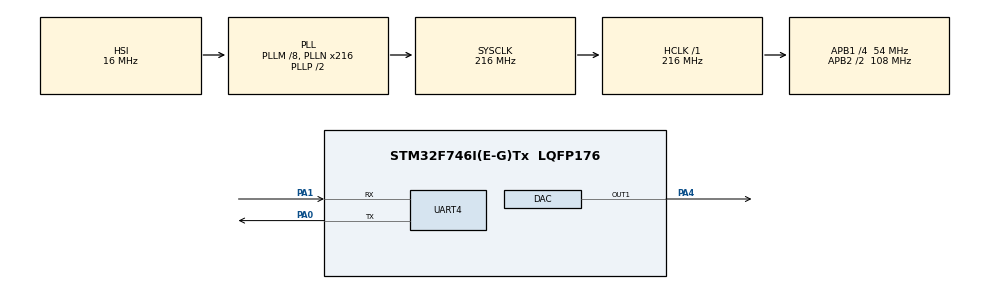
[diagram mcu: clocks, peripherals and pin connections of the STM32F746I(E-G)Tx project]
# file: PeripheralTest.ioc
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DAC.DAC_Trigger=DAC_TRIGGER_T2_TRGO
Dma.DAC1.2.Direction=DMA_MEMORY_TO_PERIPH
Dma.DAC1.2.FIFOMode=DMA_FIFOMODE_DISABLE
Dma.DAC1.2.Instance=DMA1_Stream5
Dma.DAC1.2.MemDataAlignment=DMA_MDATAALIGN_HALFWORD
Dma.DAC1.2.MemInc=DMA_MINC_ENABLE
Dma.DAC1.2.Mode=DMA_CIRCULAR
Dma.DAC1.2.PeriphDataAlignment=DMA_PDATAALIGN_HALFWORD
Dma.DAC1.2.PeriphInc=DMA_PINC_DISABLE
Dma.DAC1.2.Priority=DMA_PRIORITY_LOW
Dma.Request0=UART4_RX
Dma.Request1=UART4_TX
Dma.Request2=DAC1
Dma.UART4_RX.0.Direction=DMA_PERIPH_TO_MEMORY
Dma.UART4_RX.0.FIFOMode=DMA_FIFOMODE_DISABLE
Dma.UART4_RX.0.Instance=DMA1_Stream2
Dma.UART4_RX.0.MemDataAlignment=DMA_MDATAALIGN_BYTE
Dma.UART4_RX.0.MemInc=DMA_MINC_ENABLE
Dma.UART4_RX.0.Mode=DMA_NORMAL
Dma.UART4_RX.0.PeriphDataAlignment=DMA_PDATAALIGN_BYTE
Dma.UART4_RX.0.PeriphInc=DMA_PINC_DISABLE
Dma.UART4_RX.0.Priority=DMA_PRIORITY_LOW
Dma.UART4_TX.1.Direction=DMA_MEMORY_TO_PERIPH
Dma.UART4_TX.1.FIFOMode=DMA_FIFOMODE_DISABLE
Dma.UART4_TX.1.Instance=DMA1_Stream4
Dma.UART4_TX.1.MemDataAlignment=DMA_MDATAALIGN_BYTE
Dma.UART4_TX.1.MemInc=DMA_MINC_ENABLE
Dma.UART4_TX.1.Mode=DMA_NORMAL
Dma.UART4_TX.1.PeriphDataAlignment=DMA_PDATAALIGN_BYTE
Dma.UART4_TX.1.PeriphInc=DMA_PINC_DISABLE
Dma.UART4_TX.1.Priority=DMA_PRIORITY_LOW
FREERTOS.BinarySemaphores01=usart4Sem
FREERTOS.Tasks01=defaultTask,0,128,StartDefaultTask,Default;USARTHandle,0,128,StartUSARTTask,Default
FREERTOS.configUSE_COUNTING_SEMAPHORES=1
Mcu.Family=STM32F7
Mcu.Name=STM32F746I(E-G)Tx
Mcu.Package=LQFP176
NVIC.DMA1_Stream2_IRQn=true\:5\:0\:false\:false\:true\:true
NVIC.DMA1_Stream4_IRQn=true\:5\:0\:false\:false\:true\:true
NVIC.DMA1_Stream5_IRQn=true\:5\:0\:false\:false\:true\:true
NVIC.PriorityGroup=NVIC_PRIORITYGROUP_4
NVIC.TIM1_UP_TIM10_IRQn=true\:0\:0\:false\:false\:true\:false
NVIC.TimeBase=TIM1_UP_TIM10_IRQn
NVIC.TimeBaseIP=TIM1
NVIC.UART4_IRQn=true\:5\:0\:false\:false\:true\:true
PA0/WKUP.Mode=Asynchronous
PA0/WKUP.Signal=UART4_TX
PA1.Mode=Asynchronous
PA1.Signal=UART4_RX
PA4.Signal=COMP_DAC1_group
ProjectManager.HeapSize=0x200
ProjectManager.StackSize=0x400
ProjectManager.TargetToolchain=EWARM
RCC.AHBFreq_Value=216000000
RCC.APB1CLKDivider=RCC_HCLK_DIV4
RCC.APB1Freq_Value=54000000
RCC.APB1TimFreq_Value=108000000
RCC.APB2CLKDivider=RCC_HCLK_DIV2
RCC.APB2Freq_Value=108000000
RCC.APB2TimFreq_Value=216000000
RCC.CortexFreq_Value=216000000
RCC.HCLKFreq_Value=216000000
RCC.HSE_VALUE=25000000
RCC.HSI_VALUE=16000000
RCC.LSE_VALUE=32768
RCC.PLLM=8
RCC.PLLN=216
RCC.SYSCLKFreq_VALUE=216000000
RCC.SYSCLKSource=RCC_SYSCLKSOURCE_PLLCLK
RCC.USBFreq_Value=216000000
RCC.VCOOutputFreq_Value=432000000
SH.COMP_DAC1_group.0=DAC_OUT1,DAC_OUT1
TIM2.Period=54
TIM2.Prescaler=3
TIM2.TIM_MasterOutputTrigger=TIM_TRGO_UPDATE
UART4.WordLength=UART_WORDLENGTH_8B
VP_FREERTOS_VS_ENABLE.Mode=Enabled
VP_SYS_VS_tim1.Mode=TIM1
VP_TIM2_VS_ClockSourceITR.Mode=TriggerSource_ITR0
VP_TIM2_VS_ControllerModeTrigger.Mode=Trigger Mode
board=PeripheralTest

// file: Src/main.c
/**
  ******************************************************************************
  * File Name          : main.c
  * Description        : Main program body
  ******************************************************************************
  *
  * COPYRIGHT(c) 2017 STMicroelectronics
  *
  * Redistribution and use in source and binary forms, with or without modification,
  * are permitted provided that the following conditions are met:
  *   1. Redistributions of source code must retain the above copyright notice,
  *      this list of conditions and the following disclaimer.
  *   2. Redistributions in binary form must reproduce the above copyright notice,
  *      this list of conditions and the following disclaimer in the documentation
  *      and/or other materials provided with the distribution.
  *   3. Neither the name of STMicroelectronics nor the names of its contributors
  *      may be used to endorse or promote products derived from this software
  *      without specific prior written permission.
  *
  * THIS SOFTWARE IS PROVIDED BY THE COPYRIGHT HOLDERS AND CONTRIBUTORS "AS IS"
  * AND ANY EXPRESS OR IMPLIED WARRANTIES, INCLUDING, BUT NOT LIMITED TO, THE
  * IMPLIED WARRANTIES OF MERCHANTABILITY AND FITNESS FOR A PARTICULAR PURPOSE ARE
  * DISCLAIMED. IN NO EVENT SHALL THE COPYRIGHT HOLDER OR CONTRIBUTORS BE LIABLE
  * FOR ANY DIRECT, INDIRECT, INCIDENTAL, SPECIAL, EXEMPLARY, OR CONSEQUENTIAL
  * DAMAGES (INCLUDING, BUT NOT LIMITED TO, PROCUREMENT OF SUBSTITUTE GOODS OR
  * SERVICES; LOSS OF USE, DATA, OR PROFITS; OR BUSINESS INTERRUPTION) HOWEVER
  * CAUSED AND ON ANY THEORY OF LIABILITY, WHETHER IN CONTRACT, STRICT LIABILITY,
  * OR TORT (INCLUDING NEGLIGENCE OR OTHERWISE) ARISING IN ANY WAY OUT OF THE USE
  * OF THIS SOFTWARE, EVEN IF ADVISED OF THE POSSIBILITY OF SUCH DAMAGE.
  *
  ******************************************************************************
  */
#include "stm32f7xx_hal.h"
#include "cmsis_os.h"

/* USER CODE BEGIN Includes */
#include "stdio.h"
#include "TYPE.h"
/* USER CODE END Includes */

DAC_HandleTypeDef hdac;
DMA_HandleTypeDef hdma_dac1;

TIM_HandleTypeDef htim2;

UART_HandleTypeDef huart4;
DMA_HandleTypeDef hdma_uart4_rx;
DMA_HandleTypeDef hdma_uart4_tx;

osThreadId defaultTaskHandle;
osThreadId USARTHandleHandle;
osSemaphoreId usart4SemHandle;

/* USER CODE BEGIN PV */
/* Private variables ---------------------------------------------------------*/
data Udata;
uint16_t dacData[500];
int i=0;
int j=0;
BaseType_t err=pdFALSE;

/* USER CODE END PV */

void SystemClock_Config(void);
void Error_Handler(void);
static void MX_GPIO_Init(void);
static void MX_DMA_Init(void);
static void MX_UART4_Init(void);
static void MX_DAC_Init(void);
static void MX_TIM2_Init(void);
void StartDefaultTask(void const * argument);
void StartUSARTTask(void const * argument);

/* USER CODE BEGIN PFP */
/* Private function prototypes -----------------------------------------------*/

/* USER CODE END PFP */

int main(void)
{

  /* MCU Configuration----------------------------------------------------------*/

  /* Reset of all peripherals, Initializes the Flash interface and the Systick. */
  HAL_Init();

  /* Configure the system clock */
  SystemClock_Config();

  /* Initialize all configured peripherals */
  MX_GPIO_Init();
  MX_DMA_Init();
  MX_UART4_Init();
  MX_DAC_Init();
  MX_TIM2_Init();

  /* USER CODE BEGIN 2 */

  HAL_UART_Receive_DMA(&huart4, Udata.usart4Data, usart4MaxLen);
  __HAL_UART_ENABLE_IT(&huart4, UART_IT_IDLE);

  for(i=0,j=0;i<250;i++){
   dacData[i]=1240+j++;//1240;
  }
  for(i=250,j=0;i<500;i++){
    dacData[i]=1240+250-(j++);//1240;

  }

  HAL_DAC_Start(& hdac, DAC_CHANNEL_1);
  HAL_DAC_Start_DMA(& hdac,DAC_CHANNEL_1,(uint32_t *)dacData, 500,DAC_ALIGN_12B_R);

  HAL_TIM_Base_Start(&htim2);

  /* USER CODE END 2 */

  /* Create the semaphores(s) */
  /* definition and creation of usart4Sem */
  osSemaphoreDef(usart4Sem);
  usart4SemHandle = osSemaphoreCreate(osSemaphore(usart4Sem), 1);

  /* Create the thread(s) */
  /* definition and creation of defaultTask */
  osThreadDef(defaultTask, StartDefaultTask, osPriorityNormal, 0, 128);
  defaultTaskHandle = osThreadCreate(osThread(defaultTask), NULL);

  /* definition and creation of USARTHandle */
  osThreadDef(USARTHandle, StartUSARTTask, osPriorityNormal, 0, 128);
  USARTHandleHandle = osThreadCreate(osThread(USARTHandle), NULL);

  /* Start scheduler */
  osKernelStart();

  /* We should never get here as control is now taken by the scheduler */

  /* Infinite loop */
  while (1)
  {

  }

}

/** System Clock Configuration
*/
void SystemClock_Config(void)
{

  RCC_OscInitTypeDef RCC_OscInitStruct;
  RCC_ClkInitTypeDef RCC_ClkInitStruct;
  RCC_PeriphCLKInitTypeDef PeriphClkInitStruct;

  __HAL_RCC_PWR_CLK_ENABLE();

  __HAL_PWR_VOLTAGESCALING_CONFIG(PWR_REGULATOR_VOLTAGE_SCALE1);

  RCC_OscInitStruct.OscillatorType = RCC_OSCILLATORTYPE_HSI;
  RCC_OscInitStruct.HSIState = RCC_HSI_ON;
  RCC_OscInitStruct.HSICalibrationValue = 16;
  RCC_OscInitStruct.PLL.PLLState = RCC_PLL_ON;
  RCC_OscInitStruct.PLL.PLLSource = RCC_PLLSOURCE_HSI;
  RCC_OscInitStruct.PLL.PLLM = 8;
  RCC_OscInitStruct.PLL.PLLN = 216;
  RCC_OscInitStruct.PLL.PLLP = RCC_PLLP_DIV2;
  RCC_OscInitStruct.PLL.PLLQ = 2;
  if (HAL_RCC_OscConfig(&RCC_OscInitStruct) != HAL_OK)
  {
    Error_Handler();
  }

  if (HAL_PWREx_EnableOverDrive() != HAL_OK)
  {
    Error_Handler();
  }

  RCC_ClkInitStruct.ClockType = RCC_CLOCKTYPE_HCLK|RCC_CLOCKTYPE_SYSCLK
                              |RCC_CLOCKTYPE_PCLK1|RCC_CLOCKTYPE_PCLK2;
  RCC_ClkInitStruct.SYSCLKSource = RCC_SYSCLKSOURCE_PLLCLK;
  RCC_ClkInitStruct.AHBCLKDivider = RCC_SYSCLK_DIV1;
  RCC_ClkInitStruct.APB1CLKDivider = RCC_HCLK_DIV4;
  RCC_ClkInitStruct.APB2CLKDivider = RCC_HCLK_DIV2;
  if (HAL_RCC_ClockConfig(&RCC_ClkInitStruct, FLASH_LATENCY_7) != HAL_OK)
  {
    Error_Handler();
  }

  PeriphClkInitStruct.PeriphClockSelection = RCC_PERIPHCLK_UART4;
  PeriphClkInitStruct.Uart4ClockSelection = RCC_UART4CLKSOURCE_PCLK1;
  if (HAL_RCCEx_PeriphCLKConfig(&PeriphClkInitStruct) != HAL_OK)
  {
    Error_Handler();
  }

  HAL_SYSTICK_Config(HAL_RCC_GetHCLKFreq()/1000);

  HAL_SYSTICK_CLKSourceConfig(SYSTICK_CLKSOURCE_HCLK);

  /* SysTick_IRQn interrupt configuration */
  HAL_NVIC_SetPriority(SysTick_IRQn, 15, 0);
}

/* DAC init function */
static void MX_DAC_Init(void)
{

  DAC_ChannelConfTypeDef sConfig;

    /**DAC Initialization
    */
  hdac.Instance = DAC;
  if (HAL_DAC_Init(&hdac) != HAL_OK)
  {
    Error_Handler();
  }

    /**DAC channel OUT1 config
    */
  sConfig.DAC_Trigger = DAC_TRIGGER_T2_TRGO;
  sConfig.DAC_OutputBuffer = DAC_OUTPUTBUFFER_ENABLE;
  if (HAL_DAC_ConfigChannel(&hdac, &sConfig, DAC_CHANNEL_1) != HAL_OK)
  {
    Error_Handler();
  }

}

/* TIM2 init function */
static void MX_TIM2_Init(void)
{

  TIM_SlaveConfigTypeDef sSlaveConfig;
  TIM_MasterConfigTypeDef sMasterConfig;

  htim2.Instance = TIM2;
  htim2.Init.Prescaler = 3;
  htim2.Init.CounterMode = TIM_COUNTERMODE_UP;
  htim2.Init.Period = 54;
  htim2.Init.ClockDivision = TIM_CLOCKDIVISION_DIV1;
  if (HAL_TIM_Base_Init(&htim2) != HAL_OK)
  {
    Error_Handler();
  }

  sSlaveConfig.SlaveMode = TIM_SLAVEMODE_TRIGGER;
  sSlaveConfig.InputTrigger = TIM_TS_ITR0;
  if (HAL_TIM_SlaveConfigSynchronization(&htim2, &sSlaveConfig) != HAL_OK)
  {
    Error_Handler();
  }

  sMasterConfig.MasterOutputTrigger = TIM_TRGO_UPDATE;
  sMasterConfig.MasterSlaveMode = TIM_MASTERSLAVEMODE_DISABLE;
  if (HAL_TIMEx_MasterConfigSynchronization(&htim2, &sMasterConfig) != HAL_OK)
  {
    Error_Handler();
  }

}

/* UART4 init function */
static void MX_UART4_Init(void)
{

  huart4.Instance = UART4;
  huart4.Init.BaudRate = 115200;
  huart4.Init.WordLength = UART_WORDLENGTH_8B;
  huart4.Init.StopBits = UART_STOPBITS_1;
  huart4.Init.Parity = UART_PARITY_NONE;
  huart4.Init.Mode = UART_MODE_TX_RX;
  huart4.Init.HwFlowCtl = UART_HWCONTROL_NONE;
  huart4.Init.OverSampling = UART_OVERSAMPLING_16;
  huart4.Init.OneBitSampling = UART_ONE_BIT_SAMPLE_DISABLE;
  huart4.AdvancedInit.AdvFeatureInit = UART_ADVFEATURE_NO_INIT;
  if (HAL_UART_Init(&huart4) != HAL_OK)
  {
    Error_Handler();
  }

}

static void MX_DMA_Init(void)
{
  /* DMA controller clock enable */
  __HAL_RCC_DMA1_CLK_ENABLE();

  /* DMA interrupt init */
  /* DMA1_Stream2_IRQn interrupt configuration */
  HAL_NVIC_SetPriority(DMA1_Stream2_IRQn, 5, 0);
  HAL_NVIC_EnableIRQ(DMA1_Stream2_IRQn);
  /* DMA1_Stream4_IRQn interrupt configuration */
  HAL_NVIC_SetPriority(DMA1_Stream4_IRQn, 5, 0);
  HAL_NVIC_EnableIRQ(DMA1_Stream4_IRQn);
  /* DMA1_Stream5_IRQn interrupt configuration */
  HAL_NVIC_SetPriority(DMA1_Stream5_IRQn, 5, 0);
  HAL_NVIC_EnableIRQ(DMA1_Stream5_IRQn);

}

/** Pinout Configuration
*/
static void MX_GPIO_Init(void)
{

  /* GPIO Ports Clock Enable */
  __HAL_RCC_GPIOA_CLK_ENABLE();

}

/* StartDefaultTask function */
void StartDefaultTask(void const * argument)
{

  for(;;)
  {
    osDelay(1);
  }
}

/* StartUSARTTask function */
void StartUSARTTask(void const * argument)
{
  /* USER CODE BEGIN StartUSARTTask */
  /* Infinite loop */
  for(;;)
  {
    err=xSemaphoreTake(usart4SemHandle,portMAX_DELAY);
    if(err==pdTRUE){
        HAL_UART_DMAStop(&huart4);
        Udata.usart4Len=usart4MaxLen-hdma_uart4_rx.Instance->NDTR;
        HAL_UART_Transmit_DMA(&huart4, Udata.usart4Data, Udata.usart4Len);
        HAL_UART_Receive_DMA(&huart4, Udata.usart4Data, usart4MaxLen);
    }
    osDelay(1);
  }
  /* USER CODE END StartUSARTTask */
}

void HAL_TIM_PeriodElapsedCallback(TIM_HandleTypeDef *htim)
{
  if (htim->Instance == TIM1) {
    HAL_IncTick();
  }
}

void Error_Handler(void)
{
  while(1)
  {
  }
}

/************************ (C) COPYRIGHT STMicroelectronics *****END OF FILE****/
